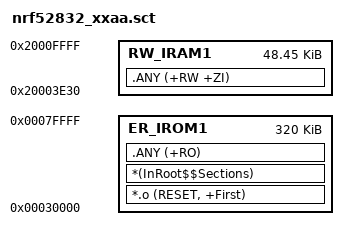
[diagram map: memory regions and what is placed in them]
; *************************************************************
; *** Scatter-Loading Description File generated by uVision ***
; *************************************************************

LR_IROM1 0x00030000 0x00050000  {    ; load region size_region
  ER_IROM1 0x00030000 0x00050000  {  ; load address = execution address
   *.o (RESET, +First)
   *(InRoot$$Sections)
   .ANY (+RO)
  }
  RW_IRAM1 0x20003E30 0x0000C1D0  {  ; RW data
   .ANY (+RW +ZI)
  }
}

